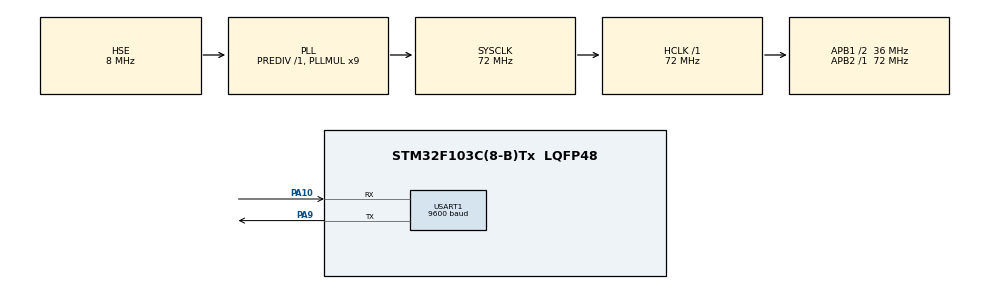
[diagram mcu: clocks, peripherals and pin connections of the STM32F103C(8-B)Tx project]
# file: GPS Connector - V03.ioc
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Mcu.Family=STM32F1
Mcu.Name=STM32F103C(8-B)Tx
Mcu.Package=LQFP48
NVIC.PriorityGroup=NVIC_PRIORITYGROUP_4
PA10.Mode=Asynchronous
PA10.Signal=USART1_RX
PA13.Mode=Serial_Wire
PA13.Signal=SYS_JTMS-SWDIO
PA14.Mode=Serial_Wire
PA14.Signal=SYS_JTCK-SWCLK
PA9.Mode=Asynchronous
PA9.Signal=USART1_TX
PC14-OSC32_IN.Mode=LSE-External-Oscillator
PC14-OSC32_IN.Signal=RCC_OSC32_IN
PC15-OSC32_OUT.Mode=LSE-External-Oscillator
PC15-OSC32_OUT.Signal=RCC_OSC32_OUT
PD0-OSC_IN.Mode=HSE-External-Oscillator
PD0-OSC_IN.Signal=RCC_OSC_IN
PD1-OSC_OUT.Mode=HSE-External-Oscillator
PD1-OSC_OUT.Signal=RCC_OSC_OUT
ProjectManager.HeapSize=0x200
ProjectManager.StackSize=0x400
ProjectManager.TargetToolchain=MDK-ARM V5.32
RCC.AHBFreq_Value=72000000
RCC.APB1CLKDivider=RCC_HCLK_DIV2
RCC.APB1Freq_Value=36000000
RCC.APB1TimFreq_Value=72000000
RCC.APB2Freq_Value=72000000
RCC.APB2TimFreq_Value=72000000
RCC.HCLKFreq_Value=72000000
RCC.PLLMUL=RCC_PLL_MUL9
RCC.PLLSourceVirtual=RCC_PLLSOURCE_HSE
RCC.SYSCLKFreq_VALUE=72000000
RCC.SYSCLKSource=RCC_SYSCLKSOURCE_PLLCLK
RCC.USBFreq_Value=72000000
USART1.BaudRate=9600
USART1.VirtualMode=VM_ASYNC
board=custom

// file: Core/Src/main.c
/* USER CODE BEGIN Header */
/**
  ******************************************************************************
  * @file           : main.c
  * @brief          : Main program body
  ******************************************************************************
  */

/* USER CODE END Header */

#include "main.h"

/* USER CODE BEGIN Includes */

#include <string.h>
#include <stdbool.h>
#include <stdlib.h>
#include <stdio.h>

/* USER CODE END Includes */

/* USER CODE BEGIN PD */

#define GPS_BUFFER_SIZE 128

/* USER CODE END PD */

UART_HandleTypeDef huart1;

/* USER CODE BEGIN PV */

uint8_t msg = 0;

uint8_t gpsData[GPS_BUFFER_SIZE];
uint16_t index = 0;

bool receivingGPS = false;
bool gpsValid = false;
bool situationGNGGA = false;

char token[10][20];

float latitudeRaw = 0.0f;
float longitudeRaw = 0.0f;

float latitude = 0.0f;
float longitude = 0.0f;

int fixQuality = 0;
int satellites = 0;
float hdop = 0.0f;
float altitude = 0.0f;

/* USER CODE END PV */

void SystemClock_Config(void);

static void MX_GPIO_Init(void);
static void MX_USART1_UART_Init(void);

/* USER CODE BEGIN PFP */

void getAllChars(void);
void tokenizeGPSData(void);

float convertLatitude(float raw);
float convertLongitude(float raw);

void processGNGGA(void);

/* USER CODE END PFP */

/* USER CODE BEGIN 0 */

/*
 * ---------------------------------------------------------
 * GPS NMEA TOKENIZER
 * ---------------------------------------------------------
 *
 * GNGGA format:
 *
 * token[0] = $GNGGA
 * token[1] = UTC
 * token[2] = Latitude
 * token[3] = N/S
 * token[4] = Longitude
 * token[5] = E/W
 * token[6] = Fix Quality
 * token[7] = Satellites
 * token[8] = HDOP
 * token[9] = Altitude
 *
 */

void tokenizeGPSData(void)
{
    int tokenIndex = 0;
    int charIndex = 0;

    /* Clear tokens */

    for (int i = 0; i < 10; i++)
    {
        token[i][0] = '\0';
    }

    /* Split GPS data by comma */

    for (int i = 0;
         gpsData[i] != '\0' && tokenIndex < 10;
         i++)
    {
        if (gpsData[i] == ',')
        {
            token[tokenIndex][charIndex] = '\0';

            tokenIndex++;
            charIndex = 0;
        }
        else
        {
            if (charIndex < 19)
            {
                token[tokenIndex][charIndex] = gpsData[i];
                charIndex++;
            }
        }
    }

    /* End last token */

    if (tokenIndex < 10)
    {
        token[tokenIndex][charIndex] = '\0';
    }
}

/*
 * ---------------------------------------------------------
 * CONVERT NMEA LATITUDE
 * ---------------------------------------------------------
 *
 * Example:
 *
 * 3542.1234
 *
 * becomes:
 *
 * 35.702056
 *
 */

float convertLatitude(float raw)
{
    int degrees;
    float minutes;

    degrees = (int)(raw / 100.0f);

    minutes = raw - (degrees * 100.0f);

    return degrees + (minutes / 60.0f);
}

/*
 * ---------------------------------------------------------
 * CONVERT NMEA LONGITUDE
 * ---------------------------------------------------------
 *
 * Example:
 *
 * 05123.4567
 *
 * becomes:
 *
 * 51.390945
 *
 */

float convertLongitude(float raw)
{
    int degrees;
    float minutes;

    degrees = (int)(raw / 100.0f);

    minutes = raw - (degrees * 100.0f);

    return degrees + (minutes / 60.0f);
}

/*
 * ---------------------------------------------------------
 * PROCESS GNGGA
 * ---------------------------------------------------------
 */

void processGNGGA(void)
{
    /*
     * Make sure this is actually GNGGA
     */

    if (strncmp((char*)gpsData, "$GNGGA", 6) != 0)
    {
        return;
    }

    situationGNGGA = true;

    /*
     * Split NMEA sentence
     */

    tokenizeGPSData();

    /*
     * Check that latitude and longitude exist
     */

    if (strlen(token[2]) == 0 || strlen(token[4]) == 0)
    {
        gpsValid = false;
        return;
    }

    /*
     * Raw Latitude
     */

    latitudeRaw = atof(token[2]);

    /*
     * Raw Longitude
     */

    longitudeRaw = atof(token[4]);

    /*
     * N/S
     */

    char latitudeDirection = token[3][0];

    /*
     * E/W
     */

    char longitudeDirection = token[5][0];

    /*
     * GPS Fix Quality
     */

    fixQuality = atoi(token[6]);

    /*
     * Number of satellites
     */

    satellites = atoi(token[7]);

    /*
     * HDOP
     */

    hdop = atof(token[8]);

    /*
     * Altitude
     */

    altitude = atof(token[9]);

    /*
     * Check GPS Fix
     */

    if (fixQuality > 0)
    {
        gpsValid = true;

        /*
         * Convert NMEA coordinates
         * to decimal degrees
         */

        latitude = convertLatitude(latitudeRaw);

        longitude = convertLongitude(longitudeRaw);

        /*
         * South latitude
         */

        if (latitudeDirection == 'S')
        {
            latitude = -latitude;
        }

        /*
         * West longitude
         */

        if (longitudeDirection == 'W')
        {
            longitude = -longitude;
        }
    }
    else
    {
        gpsValid = false;
    }
}

/*
 * ---------------------------------------------------------
 * RECEIVE GPS CHARACTERS
 * ---------------------------------------------------------
 */

void getAllChars(void)
{
    /*
     * Start of NMEA sentence
     */

    if (msg == '$')
    {
        index = 0;

        receivingGPS = true;
    }

    /*
     * Store characters
     */

    if (receivingGPS)
    {
        if (index < GPS_BUFFER_SIZE - 1)
        {
            gpsData[index] = msg;
            index++;
        }
        else
        {
            /*
             * Buffer overflow
             */

            receivingGPS = false;
            index = 0;
        }
    }

    /*
     * End of NMEA sentence
     */

    if (msg == '\n' && receivingGPS)
    {
        /*
         * Null terminate string
         */

        gpsData[index] = '\0';

        /*
         * Process only GNGGA
         */

        processGNGGA();

        /*
         * Reset buffer
         */

        receivingGPS = false;
        index = 0;
    }
}

void gpsLogic(){
	/*
	 * Receive one byte from GPS
	 */

	HAL_StatusTypeDef status;

	status = HAL_UART_Receive(
							&huart1,
							&msg,
							1,
							HAL_MAX_DELAY
					);

	/*
	 * If receiving was successful
	 */

	if (status == HAL_OK)
	{
			getAllChars();
	}
}

/* USER CODE END 0 */

int main(void)
	{

  /* MCU Configuration--------------------------------------------------------*/

  HAL_Init();

  /* Configure the system clock */

  SystemClock_Config();

  /* Initialize all configured peripherals */

  MX_GPIO_Init();

  MX_USART1_UART_Init();

  /* USER CODE BEGIN 2 */

  /*
   * Initialize variables
   */

  msg = 0;

  index = 0;

  receivingGPS = false;

  gpsValid = false;

  /* USER CODE END 2 */

  /* Infinite loop */

  while (1)
  {
		gpsLogic();
  }

}

void SystemClock_Config(void)
{
  RCC_OscInitTypeDef RCC_OscInitStruct = {0};
  RCC_ClkInitTypeDef RCC_ClkInitStruct = {0};

  RCC_OscInitStruct.OscillatorType = RCC_OSCILLATORTYPE_HSE;

  RCC_OscInitStruct.HSEState = RCC_HSE_ON;

  RCC_OscInitStruct.HSEPredivValue = RCC_HSE_PREDIV_DIV1;

  RCC_OscInitStruct.HSIState = RCC_HSI_ON;

  RCC_OscInitStruct.PLL.PLLState = RCC_PLL_ON;

  RCC_OscInitStruct.PLL.PLLSource = RCC_PLLSOURCE_HSE;

  RCC_OscInitStruct.PLL.PLLMUL = RCC_PLL_MUL9;

  if (HAL_RCC_OscConfig(&RCC_OscInitStruct) != HAL_OK)
  {
    Error_Handler();
  }

  RCC_ClkInitStruct.ClockType =
      RCC_CLOCKTYPE_HCLK |
      RCC_CLOCKTYPE_SYSCLK |
      RCC_CLOCKTYPE_PCLK1 |
      RCC_CLOCKTYPE_PCLK2;

  RCC_ClkInitStruct.SYSCLKSource = RCC_SYSCLKSOURCE_PLLCLK;

  RCC_ClkInitStruct.AHBCLKDivider = RCC_SYSCLK_DIV1;

  RCC_ClkInitStruct.APB1CLKDivider = RCC_HCLK_DIV2;

  RCC_ClkInitStruct.APB2CLKDivider = RCC_HCLK_DIV1;

  if (HAL_RCC_ClockConfig(
          &RCC_ClkInitStruct,
          FLASH_LATENCY_2) != HAL_OK)
  {
    Error_Handler();
  }
}

static void MX_USART1_UART_Init(void)
{

  huart1.Instance = USART1;

  huart1.Init.BaudRate = 9600;

  huart1.Init.WordLength = UART_WORDLENGTH_8B;

  huart1.Init.StopBits = UART_STOPBITS_1;

  huart1.Init.Parity = UART_PARITY_NONE;

  huart1.Init.Mode = UART_MODE_TX_RX;

  huart1.Init.HwFlowCtl = UART_HWCONTROL_NONE;

  huart1.Init.OverSampling = UART_OVERSAMPLING_16;

  if (HAL_UART_Init(&huart1) != HAL_OK)
  {
    Error_Handler();
  }

}

static void MX_GPIO_Init(void)
{

  __HAL_RCC_GPIOC_CLK_ENABLE();

  __HAL_RCC_GPIOD_CLK_ENABLE();

  __HAL_RCC_GPIOA_CLK_ENABLE();

}

void Error_Handler(void)
{
  __disable_irq();

  while (1)
  {
  }
}
